# CM32M4xxR register map
Vendor: CMIOT XinSheng Tech Ltd.; File version: 2.0
Registers are 32-bit, read-write, reset 0x0 unless marked. A register's access mark holds for its fields unless they carry their own. Offsets are from the block's base; [hi:lo] are bit positions; {n}, {i} and the like mark numbered series.

## IWDG — Independent watchdog
Base 0x40003000
0x00 IWDG_KEY
  [15:0] KEYV
0x04 IWDG_PREDIV
  [2:0] PD
0x08 IWDG_RELV reset 0xFFF
  [11:0] REL
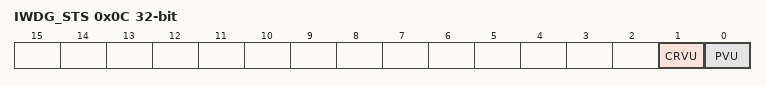
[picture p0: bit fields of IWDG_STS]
0x0C IWDG_STS
  [1] CRVU, [0] PVU

## WWDG — Window watchdog
Base 0x40002C00
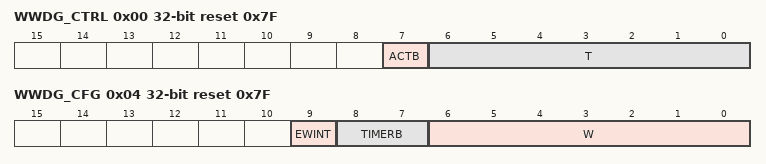
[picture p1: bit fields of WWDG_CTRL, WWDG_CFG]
0x00 WWDG_CTRL reset 0x7F
  [7] ACTB
  [6:0] T — T Timer
0x04 WWDG_CFG reset 0x7F (reset mask 0xFF)
  [9] EWINT, [8:7] TIMERB, [6:0] W
0x08 WWDG_STS
  [0] EWINTF

## PWR — Power control
Base 0x40007000
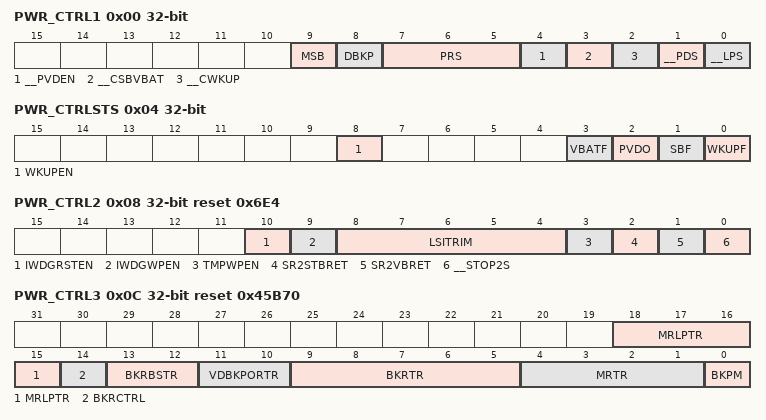
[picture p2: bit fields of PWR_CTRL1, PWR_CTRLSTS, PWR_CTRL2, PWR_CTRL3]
0x00 PWR_CTRL1
  [9] MSB, [8] DBKP, [7:5] PRS, [4] __PVDEN, [3] __CSBVBAT, [2] __CWKUP, [1] __PDS, [0] __LPS
0x04 PWR_CTRLSTS
  [8] WKUPEN, [3] VBATF, [2] PVDO, [1] SBF, [0] WKUPF
0x08 PWR_CTRL2 reset 0x6E4
  [10] IWDGRSTEN, [9] IWDGWPEN, [8:4] LSITRIM, [3] TMPWPEN, [2] SR2STBRET, [1] SR2VBRET, [0] __STOP2S
0x0C PWR_CTRL3 reset 0x45B70
  [18:15] MRLPTR, [14] BKRCTRL, [13:12] BKRBSTR, [11:10] VDBKPORTR, [9:5] BKRTR, [4:1] MRTR, [0] BKPM
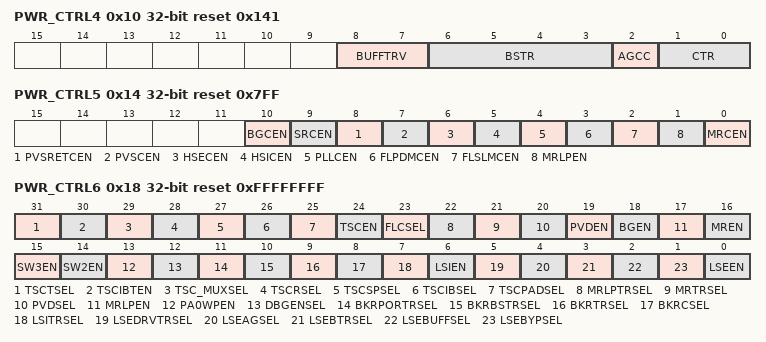
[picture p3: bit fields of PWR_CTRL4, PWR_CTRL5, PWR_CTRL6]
0x10 PWR_CTRL4 reset 0x141
  [8:7] BUFFTRV, [6:3] BSTR, [2] AGCC, [1:0] CTR
0x14 PWR_CTRL5 reset 0x7FF
  [10] BGCEN, [9] SRCEN, [8] PVSRETCEN, [7] PVSCEN, [6] HSECEN, [5] HSICEN, [4] PLLCEN, [3] FLPDMCEN, [2] FLSLMCEN, [1] MRLPEN, [0] MRCEN
0x18 PWR_CTRL6 reset 0xFFFFFFFF
  [31] TSCTSEL, [30] TSCIBTEN, [29] TSC_MUXSEL, [28] TSCRSEL, [27] TSCSPSEL, [26] TSCIBSEL, [25] TSCPADSEL, [24] TSCEN, [23] FLCSEL, [22] MRLPTRSEL, [21] MRTRSEL, [20] PVDSEL, [19] PVDEN, [18] BGEN, [17] MRLPEN, [16] MREN, [15] SW3EN, [14] SW2EN, [13] PA0WPEN, [12] DBGENSEL, [11] BKRPORTRSEL, [10] BKRBSTRSEL, [9] BKRTRSEL, [8] BKRCSEL, [7] LSITRSEL, [6] LSIEN, [5] LSEDRVTRSEL, [4] LSEAGSEL, [3] LSEBTRSEL, [2] LSEBUFFSEL, [1] LSEBYPSEL, [0] LSEEN
0x1C PWR_CTRL7 reset 0x1
  [0] PVSCSEL

## QSPI — Queued SPI
Base 0xA0001000
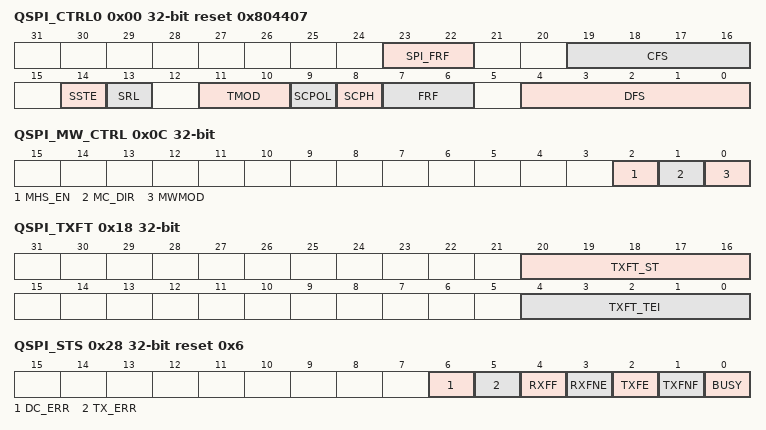
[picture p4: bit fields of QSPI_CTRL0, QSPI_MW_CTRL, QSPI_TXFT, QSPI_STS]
0x00 QSPI_CTRL0 reset 0x804407
  [23:22] SPI_FRF, [19:16] CFS, [14] SSTE, [13] SRL, [11:10] TMOD, [9] SCPOL, [8] SCPH, [7:6] FRF, [4:0] DFS
0x04 QSPI_CTRL1
  [15:0] NDF
0x08 QSPI_EN
  [0] QEN
0x0C QSPI_MW_CTRL
  [2] MHS_EN, [1] MC_DIR, [0] MWMOD
0x10 QSPI_SLAVE_EN
  [0] SEN
0x14 QSPI_BAUD
  [15:0] CLK_DIV
0x18 QSPI_TXFT
  [20:16] TXFT_ST, [4:0] TXFT_TEI
0x1C QSPI_RXFT
  [4:0] RXFT_TFI
0x20 QSPI_TXFN
  [5:0] TXFN
0x24 QSPI_RXFN
  [5:0] RXFN
0x28 QSPI_STS reset 0x6
  [6] DC_ERR, [5] TX_ERR, [4] RXFF, [3] RXFNE, [2] TXFE, [1] TXFNF, [0] BUSY
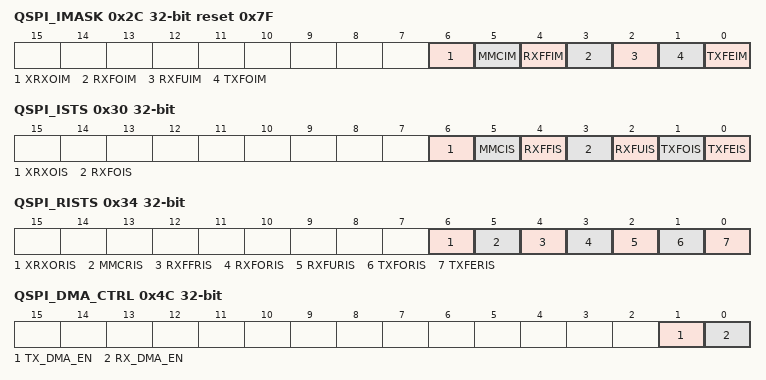
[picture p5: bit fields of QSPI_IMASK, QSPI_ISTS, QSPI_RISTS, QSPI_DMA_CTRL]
0x2C QSPI_IMASK reset 0x7F
  [6] XRXOIM, [5] MMCIM, [4] RXFFIM, [3] RXFOIM, [2] RXFUIM, [1] TXFOIM, [0] TXFEIM
0x30 QSPI_ISTS
  [6] XRXOIS, [5] MMCIS, [4] RXFFIS, [3] RXFOIS, [2] RXFUIS, [1] TXFOIS, [0] TXFEIS
0x34 QSPI_RISTS
  [6] XRXORIS, [5] MMCRIS, [4] RXFFRIS, [3] RXFORIS, [2] RXFURIS, [1] TXFORIS, [0] TXFERIS
0x38 QSPI_TXFOI_CLR
  [0] TXFOIC
0x3C QSPI_RXFOI_CLR
  [0] RXFOIC
0x40 QSPI_RXFUI_CLR
  [0] RXFUIC
0x44 QSPI_MMC_CLR
  [0] MMCIC
0x48 QSPI_ICLR
  [0] INTC
0x4C QSPI_DMA_CTRL
  [1] TX_DMA_EN, [0] RX_DMA_EN
0x50 QSPI_DMATDL_CTRL
  [5:0] DMATDL
0x54 QSPI_DMARDL_CTRL
  [5:0] DMARDL
0x58 QSPI_IDCODE reset 0xFFFFFFFF
0x60 QSPI_DATx
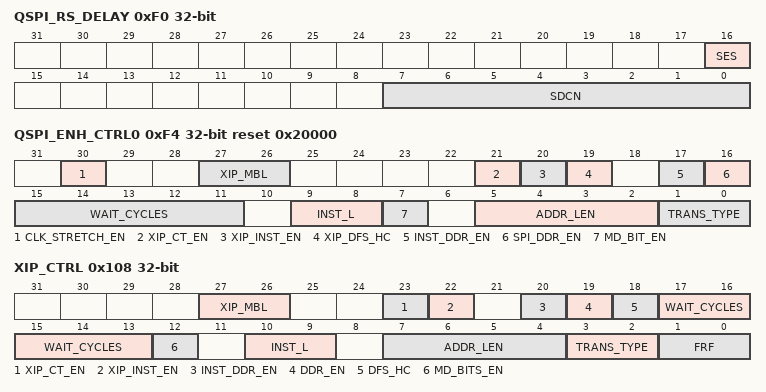
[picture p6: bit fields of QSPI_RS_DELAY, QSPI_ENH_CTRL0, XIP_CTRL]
0xF0 QSPI_RS_DELAY
  [16] SES, [7:0] SDCN
0xF4 QSPI_ENH_CTRL0 reset 0x20000
  [30] CLK_STRETCH_EN, [27:26] XIP_MBL, [21] XIP_CT_EN, [20] XIP_INST_EN, [19] XIP_DFS_HC, [17] INST_DDR_EN, [16] SPI_DDR_EN, [15:11] WAIT_CYCLES, [9:8] INST_L, [7] MD_BIT_EN, [5:2] ADDR_LEN, [1:0] TRANS_TYPE
0xF8 QSPI_DDR_TXDE
  [7:0] TXDE
0xFC XIP_MODE
  [15:0] XIP_MD_BITS
0x100 XIP_INCR_TOC
  [15:0] ITOC
0x104 XIP_WRAP_TOC
  [15:0] WTOC
0x108 XIP_CTRL
  [27:26] XIP_MBL, [23] XIP_CT_EN, [22] XIP_INST_EN, [20] INST_DDR_EN, [19] DDR_EN, [18] DFS_HC, [17:13] WAIT_CYCLES, [12] MD_BITS_EN, [10:9] INST_L, [7:4] ADDR_LEN, [3:2] TRANS_TYPE, [1:0] FRF
0x10C XIP_SLAVE_EN
  [0] SEN
0x110 XIP_RXFOI_CLR
  [0] XRXFOIC
0x114 XIP_TOUT
  [7:0] XTOUT

## RCC — Reset and clock control
Base 0x40021000
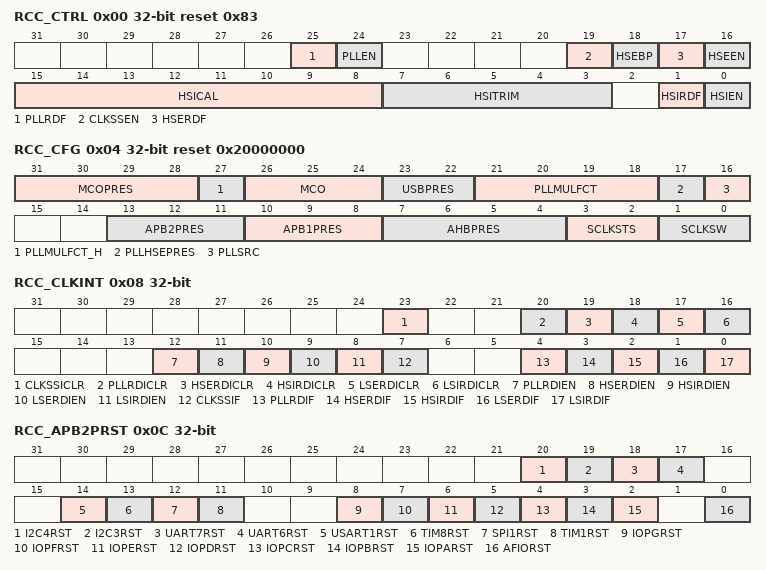
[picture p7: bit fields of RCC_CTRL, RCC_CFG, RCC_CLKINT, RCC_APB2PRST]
0x00 RCC_CTRL reset 0x83
  [25] PLLRDF, [24] PLLEN, [19] CLKSSEN, [18] HSEBP, [17] HSERDF, [16] HSEEN, [15:8] HSICAL, [7:3] HSITRIM, [1] HSIRDF, [0] HSIEN
0x04 RCC_CFG reset 0x20000000
  [31:28] MCOPRES, [27] PLLMULFCT_H, [26:24] MCO, [23:22] USBPRES, [21:18] PLLMULFCT, [17] PLLHSEPRES, [16] PLLSRC, [13:11] APB2PRES, [10:8] APB1PRES, [7:4] AHBPRES, [3:2] SCLKSTS, [1:0] SCLKSW
0x08 RCC_CLKINT
  [23] CLKSSICLR, [20] PLLRDICLR, [19] HSERDICLR, [18] HSIRDICLR, [17] LSERDICLR, [16] LSIRDICLR, [12] PLLRDIEN, [11] HSERDIEN, [10] HSIRDIEN, [9] LSERDIEN, [8] LSIRDIEN, [7] CLKSSIF, [4] PLLRDIF, [3] HSERDIF, [2] HSIRDIF, [1] LSERDIF, [0] LSIRDIF
0x0C RCC_APB2PRST
  [20] I2C4RST, [19] I2C3RST, [18] UART7RST, [17] UART6RST, [14] USART1RST, [13] TIM8RST, [12] SPI1RST, [11] TIM1RST, [8] IOPGRST, [7] IOPFRST, [6] IOPERST, [5] IOPDRST, [4] IOPCRST, [3] IOPBRST, [2] IOPARST, [0] AFIORST
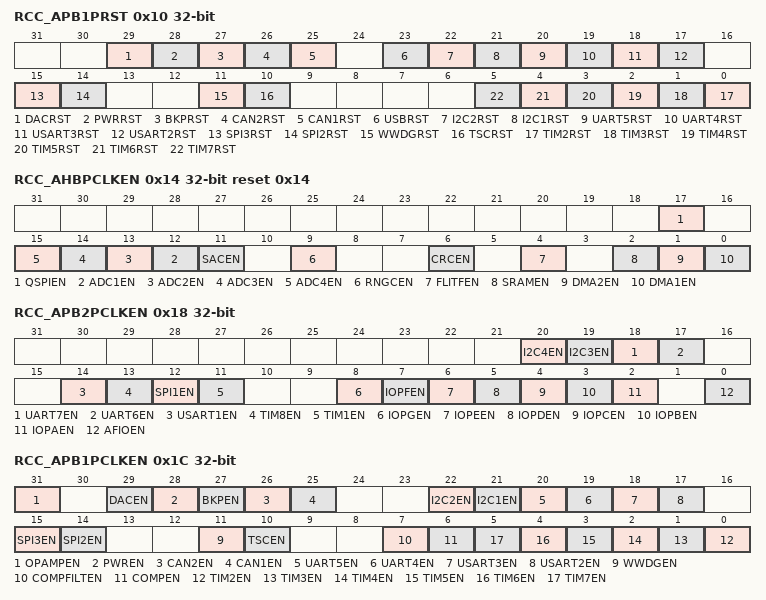
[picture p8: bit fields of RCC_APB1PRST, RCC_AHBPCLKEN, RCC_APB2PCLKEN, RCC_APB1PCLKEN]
0x10 RCC_APB1PRST
  [29] DACRST, [28] PWRRST, [27] BKPRST, [26] CAN2RST, [25] CAN1RST, [23] USBRST, [22] I2C2RST, [21] I2C1RST, [20] UART5RST, [19] UART4RST, [18] USART3RST, [17] USART2RST, [15] SPI3RST, [14] SPI2RST, [11] WWDGRST, [10] TSCRST, [n-2] TIM{n}RST (n=2..7)
0x14 RCC_AHBPCLKEN reset 0x14
  [17] QSPIEN, [n+11] ADC{n}EN (n=1..4), [11] SACEN, [9] RNGCEN, [6] CRCEN, [4] FLITFEN, [2] SRAMEN, [1] DMA2EN, [0] DMA1EN
0x18 RCC_APB2PCLKEN
  [20] I2C4EN, [19] I2C3EN, [18] UART7EN, [17] UART6EN, [14] USART1EN, [13] TIM8EN, [12] SPI1EN, [11] TIM1EN, [8] IOPGEN, [7] IOPFEN, [6] IOPEEN, [5] IOPDEN, [4] IOPCEN, [3] IOPBEN, [2] IOPAEN, [0] AFIOEN
0x1C RCC_APB1PCLKEN
  [31] OPAMPEN, [29] DACEN, [28] PWREN, [27] BKPEN, [26] CAN2EN, [25] CAN1EN, [22] I2C2EN, [21] I2C1EN, [20] UART5EN, [19] UART4EN, [18] USART3EN, [17] USART2EN, [15] SPI3EN, [14] SPI2EN, [11] WWDGEN, [10] TSCEN, [7] COMPFILTEN, [6] COMPEN, [n-2] TIM{n}EN (n=2..7)
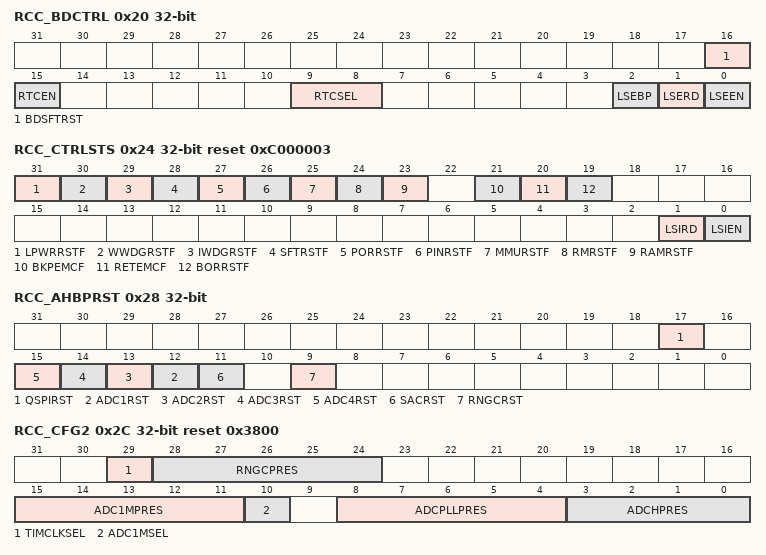
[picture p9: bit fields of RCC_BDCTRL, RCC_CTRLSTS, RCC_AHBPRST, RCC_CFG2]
0x20 RCC_BDCTRL
  [16] BDSFTRST
  [15] RTCEN
  [9:8] RTCSEL
  [2] LSEBP
  [1] LSERD — LSERDIF
  [0] LSEEN
0x24 RCC_CTRLSTS reset 0xC000003
  [31] LPWRRSTF, [30] WWDGRSTF, [29] IWDGRSTF, [28] SFTRSTF, [27] PORRSTF, [26] PINRSTF, [25] MMURSTF, [24] RMRSTF, [23] RAMRSTF, [21] BKPEMCF, [20] RETEMCF, [19] BORRSTF, [1] LSIRD, [0] LSIEN
0x28 RCC_AHBPRST
  [17] QSPIRST, [n+11] ADC{n}RST (n=1..4), [11] SACRST, [9] RNGCRST
0x2C RCC_CFG2 reset 0x3800
  [29] TIMCLKSEL, [28:24] RNGCPRES, [15:11] ADC1MPRES, [10] ADC1MSEL, [8:4] ADCPLLPRES, [3:0] ADCHPRES
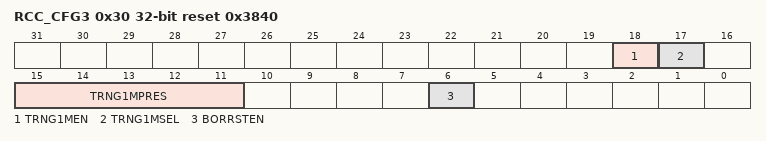
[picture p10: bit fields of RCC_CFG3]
0x30 RCC_CFG3 reset 0x3840
  [18] TRNG1MEN, [17] TRNG1MSEL, [15:11] TRNG1MPRES, [6] BORRSTEN
